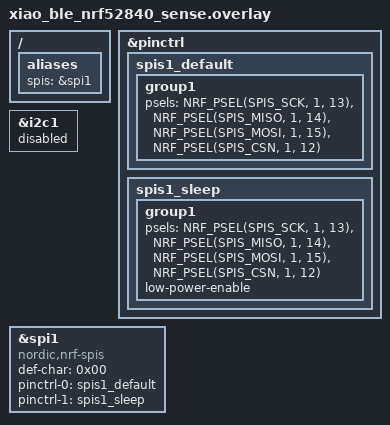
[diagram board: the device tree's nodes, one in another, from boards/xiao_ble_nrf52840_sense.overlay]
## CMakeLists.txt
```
# Copyright (c) 2026 Jjateen Gundesha <jjateen97@gmail.com>
# SPDX-License-Identifier: Apache-2.0

cmake_minimum_required(VERSION 3.20.0)
find_package(Zephyr REQUIRED HINTS $ENV{ZEPHYR_BASE})
project(spis_async)
target_sources(app PRIVATE src/main.c)
```

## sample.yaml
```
sample:
  name: SPI slave async callback
tests:
  sample.drivers.spis.async:
    tags:
      - drivers
      - spi
    depends_on: spi
    platform_allow:
      - xiao_ble/nrf52840/sense
    integration_platforms:
      - xiao_ble/nrf52840/sense
    harness: console
    harness_config:
      type: one_line
      regex:
        - ".*spis_async: Waiting for SPI master transfer"
```

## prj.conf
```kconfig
CONFIG_LOG=y
CONFIG_SPI=y
CONFIG_SPI_ASYNC=y
```

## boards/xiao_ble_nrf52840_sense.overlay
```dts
/*
 * Copyright (c) 2026 Jjateen Gundesha <jjateen97@gmail.com>
 * SPDX-License-Identifier: Apache-2.0
 *
 * XIAO nRF52840 Sense pin mapping (XIAO connector):
 *   D8 / P1.13 -> SPIS SCK
 *   D9 / P1.14 -> SPIS MISO
 *  D10 / P1.15 -> SPIS MOSI
 *   D7 / P1.12 -> SPIS CSN
 *
 * spi1 (0x40004000) is used as SPIS; it shares the peripheral address with
 * i2c1 so both cannot be enabled simultaneously.
 */

&pinctrl {
	spis1_default: spis1_default {
		group1 {
			psels = <NRF_PSEL(SPIS_SCK,  1, 13)>,
				<NRF_PSEL(SPIS_MISO, 1, 14)>,
				<NRF_PSEL(SPIS_MOSI, 1, 15)>,
				<NRF_PSEL(SPIS_CSN,  1, 12)>;
		};
	};

	spis1_sleep: spis1_sleep {
		group1 {
			psels = <NRF_PSEL(SPIS_SCK,  1, 13)>,
				<NRF_PSEL(SPIS_MISO, 1, 14)>,
				<NRF_PSEL(SPIS_MOSI, 1, 15)>,
				<NRF_PSEL(SPIS_CSN,  1, 12)>;
			low-power-enable;
		};
	};
};

/* Disable i2c1 since it shares the peripheral with spi1 */
&i2c1 {
	status = "disabled";
};

&spi1 {
	compatible = "nordic,nrf-spis";
	status = "okay";
	def-char = <0x00>;
	pinctrl-0 = <&spis1_default>;
	pinctrl-1 = <&spis1_sleep>;
	pinctrl-names = "default", "sleep";
};

/ {
	aliases {
		spis = &spi1;
	};
};
```

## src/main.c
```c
/*
 * Copyright (c) 2026 Jjateen Gundesha <jjateen97@gmail.com>
 *
 * SPDX-License-Identifier: Apache-2.0
 */

/**
 * @file
 * @brief SPI slave async callback sample
 *
 * Demonstrates how to use spi_transceive_cb() to receive a transfer
 * completion notification via callback, equivalent to nrfx spis_event_handler
 * with NRF_DRV_SPIS_XFER_DONE. The device waits for a SPI master to initiate
 * a transfer and prints the received data on completion.
 */

#include <zephyr/kernel.h>
#include <zephyr/drivers/spi.h>
#include <zephyr/logging/log.h>

LOG_MODULE_REGISTER(spis_async, LOG_LEVEL_INF);

#define BUF_SIZE 32

static const struct device *const spis_dev = DEVICE_DT_GET(DT_ALIAS(spis));
static const struct spi_config spis_cfg = {
	.operation = SPI_OP_MODE_SLAVE | SPI_WORD_SET(8) | SPI_TRANSFER_MSB,
};

static K_SEM_DEFINE(xfer_done, 0, 1);
static int xfer_result;

static uint8_t tx_buf[BUF_SIZE] = "Hello from SPIS async!";
static uint8_t rx_buf[BUF_SIZE];

/**
 * @brief Transfer completion callback - equivalent to spis_event_handler with
 *        NRF_DRV_SPIS_XFER_DONE check in the legacy nrfx API.
 *
 * This runs in the context of the SPI driver work queue after EasyDMA
 * completes. Do minimal work here; signal a semaphore and process in main.
 */
static void spis_callback(const struct device *dev, int result, void *userdata)
{
	ARG_UNUSED(dev);
	ARG_UNUSED(userdata);

	xfer_result = result;
	k_sem_give(&xfer_done);
}

int main(void)
{
	int ret;
	struct spi_buf tx_spi_buf = {.buf = tx_buf, .len = sizeof(tx_buf)};
	struct spi_buf rx_spi_buf = {.buf = rx_buf, .len = sizeof(rx_buf)};
	struct spi_buf_set tx_set = {.buffers = &tx_spi_buf, .count = 1};
	struct spi_buf_set rx_set = {.buffers = &rx_spi_buf, .count = 1};

	if (!device_is_ready(spis_dev)) {
		LOG_ERR("SPIS device not ready");
		return -ENODEV;
	}

	LOG_INF("SPIS async sample started on %s", CONFIG_BOARD_TARGET);

	while (1) {
		memset(rx_buf, 0, sizeof(rx_buf));

		LOG_INF("Waiting for SPI master transfer...");

		/*
		 * spi_transceive_cb() arms the SPIS peripheral and returns
		 * immediately. spis_callback() fires when the master completes
		 * the transfer - this is the Zephyr equivalent of registering
		 * spis_event_handler and checking NRF_DRV_SPIS_XFER_DONE.
		 */
		ret = spi_transceive_cb(spis_dev, &spis_cfg,
					 &tx_set, &rx_set,
					 spis_callback, NULL);
		if (ret < 0) {
			LOG_ERR("spi_transceive_cb failed: %d", ret);
			return ret;
		}

		/* Block until callback signals completion */
		k_sem_take(&xfer_done, K_FOREVER);

		if (xfer_result < 0) {
			LOG_ERR("Transfer error: %d", xfer_result);
			continue;
		}

		LOG_INF("Transfer complete: %.*s",
			(int)sizeof(rx_buf), rx_buf);
	}

	return 0;
}
```
